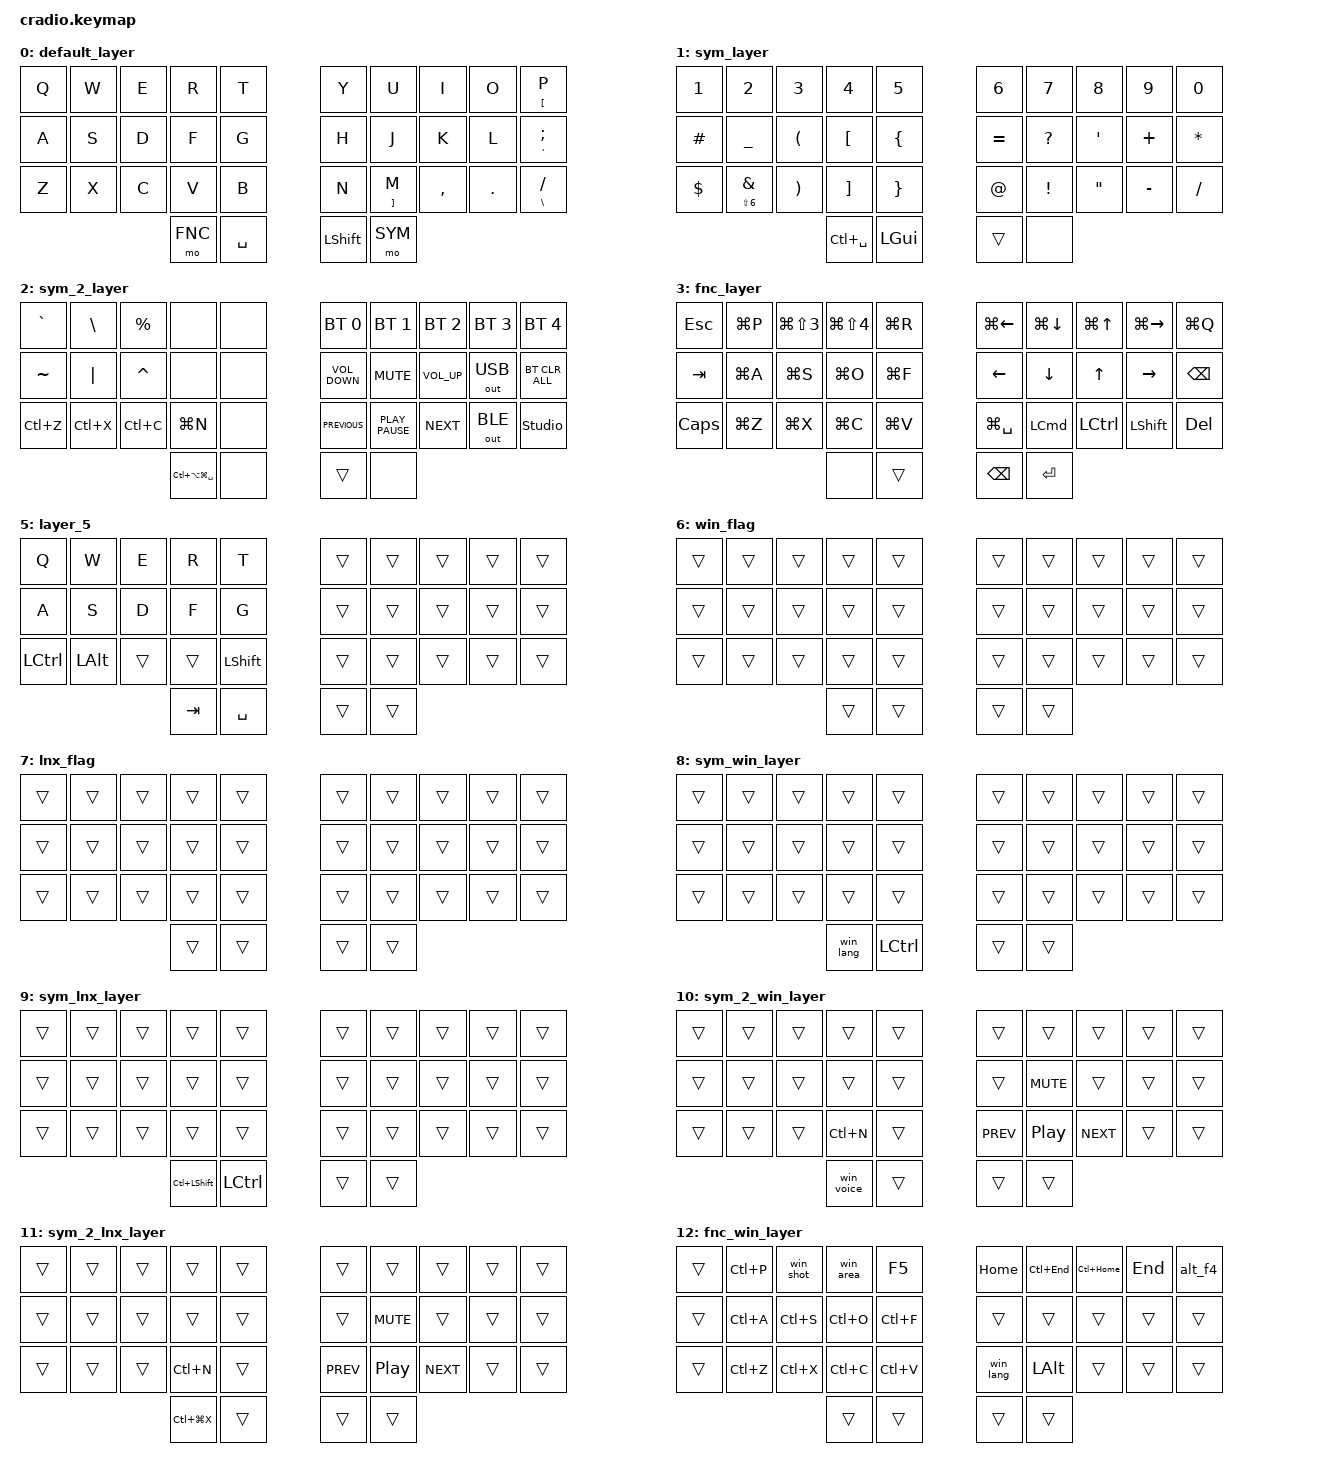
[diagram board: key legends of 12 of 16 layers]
/*
 * Copyright (c) 2020 The ZMK Contributors
 *
 * SPDX-License-Identifier: MIT
 */

#include <behaviors.dtsi>
#include <dt-bindings/zmk/bt.h>
#include <dt-bindings/zmk/keys.h>
#include <dt-bindings/zmk/outputs.h>

#define QWERTY  0
#define SYM     1
#define SYM_2   2
#define FNC     3
#define FNC_2   4
#define GAME    5

/*
 * Режимы ОС.
 *
 * Раскладка одна на все машины: буквы, цифры и символы от ОС не зависят.
 * Зависят сочетания — на Маке копирование это ⌘C, в Windows Ctrl+C, в Omarchy
 * Super+C. Поэтому базой остаётся Мак (основная машина), а под Windows и Linux
 * поднимается ПУСТОЙ флаг-слой, сам по себе ничего не делающий. Через
 * conditional_layers пара «флаг + рабочий слой» поднимает накладку *_W / *_L, в
 * которой переопределены ТОЛЬКО отличающиеся клавиши, остальные &trans и
 * проваливаются на маковские.
 *
 * Режим выбирается сам по BLE-профилю: профиль 1 — Мак, профиль 2 — Windows,
 * профиль 3 — Linux (dongle/src/os_profile.c слушает смену профиля). Вручную —
 * парные нажатия на слое SYM_2: R+T это Мак, F+G это Windows, V+B это Linux
 * (нужно при выводе по USB, где профиля нет). Одиночных клавиш режима тут
 * больше нет: слой SYM_2 включается комбо больших пальцев сам, и буква из
 * того столбца меняла режим при обычной печати. Ручной выбор держится до
 * следующей СМЕНЫ профиля: переподключение хоста его не сбивает.
 *
 * Номера слоёв ниже дублируются в Kconfig донгла (SWEEP_DONGLE_OS_LAYER_*) и в
 * layer_names[] в dongle/src/screen.c — при перестановке слоёв править и там.
 */
#define WIN      6
#define LNX      7
#define SYM_W    8
#define SYM_L    9
#define SYM_2_W 10
#define SYM_2_L 11
#define FNC_W   12
#define FNC_L   13
#define FNC_2_W 14
#define FNC_2_L 15

/*
 * Вызов голосового ввода.
 *
 * Мак: Handy по Ctrl+Alt+Cmd+Space. Сочетание выбрано после разбора
 * com.apple.symbolichotkeys.plist: ни одно из 34 включённых системных
 * сочетаний macOS не использует эту комбинацию модификаторов. Три модификатора
 * вдобавок практически исключают совпадение с сочетаниями внутри программ.
 * Это же сочетание нужно назначить в самом Handy — клавиатура его лишь шлёт.
 *
 * Windows: встроенный голосовой набор Win+H. Omarchy: voxtype, Super+Ctrl+X.
 */
#define VOICE_MAC &kp LC(LA(LG(SPACE)))
#define VOICE_WIN &win_voice
#define VOICE_LNX &kp LC(LG(X))

/* Смена раскладки RU/EN. Мак — Ctrl+Space, Windows — Win+Space, Omarchy —
   Ctrl+Shift (так настроено у владельца). */
#define LANG_WIN &win_lang
#define LANG_LNX &kp LC(LSHFT)

/*
 * Выбор выхода: USB или BLE.
 *
 * ZMK стартует с preferred_transport = ZMK_TRANSPORT_USB и меняет его ТОЛЬКО
 * биндингом &out; значение потом лежит в настройках. Пока готовы оба выхода,
 * побеждает USB — то есть любой воткнутый кабель, хоть для зарядки донгла,
 * хоть для снятия логов, молча уводит нажатия с BLE. Со стороны это выглядит
 * как «клавиатура не печатает по BLE», хотя половинки, донгл и мак исправны.
 *
 * Без этих двух клавиш вернуть вывод на BLE было нечем: Kconfig на выбор
 * выхода в ZMK нет, только поведение &out.
 */

&mt {
    //  flavor = "tap-preferred";
    // tapping_term_ms = <200>;
};

/ {
    behaviors {
        /*
         * Символ удержанием на буквах P/[, ;/', M/], //\.
         *
         * Тест 11.11.2026 на Windows: при 150 мс без защиты от печати удержание
         * срабатывало посреди слова — «съешъ» вместо «съешь» (M нажата через
         * 150 мс после предыдущей буквы и продержана чуть дольше порога), «\»
         * вместо знака препинания. Сознательное удержание P->[ при этом не
         * получалось.
         *
         * require-prior-idle-ms: нажатие в пределах 200 мс после другой клавиши
         * сразу считается тапом — внутри слова символ удержания не выскочит, и
         * следующей клавише не надо ждать решения. Удержание работает после
         * паузы, как и задумано для скобок и обратного слэша.
         * tapping-term-ms 150 -> 200: медленное одиночное нажатие реже уходит в
         * удержание. Раньше было 300 — от него отказались из-за задержки, а
         * задержку внутри печати теперь снимает require-prior-idle-ms.
         * quick-tap-ms: повторное нажатие той же клавиши с удержанием —
         * автоповтор буквы, а не символ.
         */
        dc: dot_comma {
            compatible = "zmk,behavior-hold-tap";
            #binding-cells = <2>;
            tapping-term-ms = <200>;
            require-prior-idle-ms = <200>;
            quick-tap-ms = <200>;
            flavor = "tap-preferred";
            bindings = <&kp>, <&kp>;
        };

        /* ⌘⌫ с Мака: стереть до начала строки. В Windows и Linux отдельного
           сочетания нет, поэтому выделяем до начала строки и стираем. */
        del_bol: delete_to_line_start {
            compatible = "zmk,behavior-macro";
            #binding-cells = <0>;
            bindings = <&kp LS(HOME) &kp BSPC>;
        };
    };

    /*
     * Сочетания с клавишей Win, разнесённые по времени.
     *
     * `&kp LG(SPACE)` отдаёт модификатор и клавишу практически одним HID-
     * отчётом, и Windows успевает увидеть только Win: на отпускании
     * открывается «Пуск», а язык не переключается. Меню «Пуск» в Windows
     * открывается по ОДИНОЧНОМУ нажатию Win, поэтому любая промашка с
     * порядком отчётов выглядит именно так.
     *
     * Макрос давит Win, ждёт, отдельным отчётом тапает клавишу и только потом
     * отпускает Win. 30 мс на шаг — с запасом для обработчика оболочки и
     * незаметно на руке: всё сочетание укладывается в 90 мс.
     *
     * На Маке и в Omarchy этой беды нет, там `&kp` с модификатором оставлен.
     */
    macros {
        win_lang: windows_language_switch {
            compatible = "zmk,behavior-macro";
            #binding-cells = <0>;
            wait-ms = <30>;
            tap-ms = <30>;
            bindings = <&macro_press &kp LGUI>
                     , <&macro_tap &kp SPACE>
                     , <&macro_release &kp LGUI>;
        };

        win_voice: windows_voice_typing {
            compatible = "zmk,behavior-macro";
            #binding-cells = <0>;
            wait-ms = <30>;
            tap-ms = <30>;
            bindings = <&macro_press &kp LGUI>
                     , <&macro_tap &kp H>
                     , <&macro_release &kp LGUI>;
        };

        win_shot: windows_screenshot {
            compatible = "zmk,behavior-macro";
            #binding-cells = <0>;
            wait-ms = <30>;
            tap-ms = <30>;
            bindings = <&macro_press &kp LGUI>
                     , <&macro_tap &kp PSCRN>
                     , <&macro_release &kp LGUI>;
        };

        /*
         * Alt+F4 и Alt+Tab тоже макросами: Windows требует, чтобы Alt был
         * зажат ДО клавиши, а одним HID-отчётом это не гарантируется.
         * Alt+Tab одиночным тапом переключает на предыдущее окно — именно то,
         * чего ждёшь от «переключить окно».
         */
        alt_f4: windows_close_window {
            compatible = "zmk,behavior-macro";
            #binding-cells = <0>;
            wait-ms = <30>;
            tap-ms = <30>;
            bindings = <&macro_press &kp LALT>
                     , <&macro_tap &kp F4>
                     , <&macro_release &kp LALT>;
        };

        alt_tab: switch_window {
            compatible = "zmk,behavior-macro";
            #binding-cells = <0>;
            wait-ms = <30>;
            tap-ms = <30>;
            bindings = <&macro_press &kp LALT>
                     , <&macro_tap &kp TAB>
                     , <&macro_release &kp LALT>;
        };

        win_area: windows_screenshot_area {
            compatible = "zmk,behavior-macro";
            #binding-cells = <0>;
            wait-ms = <30>;
            tap-ms = <30>;
            bindings = <&macro_press &kp LGUI &kp LSHFT>
                     , <&macro_tap &kp S>
                     , <&macro_release &kp LSHFT &kp LGUI>;
        };
    };

    /*
     * ZMK придерживает нажатие клавиши, входящей в комбо, на
     * min(время удержания, timeout-ms) — `app/src/combo.c`, `position_state_down`.
     * Для клавиш, которые держат (&mo, Shift), это всегда полный timeout-ms
     * (zmkfirmware/zmk#2281). Замер 02.10.2026: при 50 мс задерживалось каждое
     * третье нажатие большими пальцами.
     *
     * 30.10.2026 по решению владельца timeout-ms = 25 на всех комбо. При пробе
     * 25 мс на пальцах раньше собирать их было тяжело: если комбо перестанут
     * срабатывать, смотреть сюда.
     */
    combos {
        compatible = "zmk,combos";

        /*
         * ВЕРНУЛИСЬ 08.10.2026. Попытка убрать комбо и переключать слои
         * клавишей внутри слоя провалилась: &tog встал на пальцы Shift и
         * пробела, и обычный порядок «зажать SYM, нажать Shift» стал
         * переключать слой вместо шифта. Пока нет проверенной замены, лучше
         * платить 50 мс на каждом третьем нажатии, чем терять Shift.
         *
         * Цена задержки измерена и описана в README шилда; замена будет
         * выбрана по разбору реальных раскладок, а не на ходу.
         */
        combo_sym2 {
            timeout-ms = <25>;
            require-prior-idle-ms = <150>;
            key-positions = <32 33>;
            bindings = <&tog SYM_2>;
        };

        combo_fun2 {
            timeout-ms = <25>;
            require-prior-idle-ms = <150>;
            key-positions = <30 31>;
            bindings = <&tog FNC_2>;
        };

        /*
         * Ручной выбор режима ОС — ПАРНЫМИ нажатиями, а не одиночной клавишей.
         *
         * Одиночные стояли на SYM_2 в столбце T/G/B и приводили к «раскладка
         * сама меняется с mac на lnx при живом профиле BT1»: слой SYM_2
         * включается комбо больших пальцев само, при обычном накате, и буква
         * из этого столбца попадала по клавише режима. Пара соседних клавиш в
         * пределах 50 мс случайно не собирается.
         *
         * layers перечислены все три, потому что ZMK сверяет комбо с САМЫМ
         * ВЕРХНИМ активным слоем (combo.c: zmk_keymap_highest_layer_active), а
         * в режимах Windows и Linux поверх SYM_2 стоит его накладка.
         */
        combo_os_mac {
            timeout-ms = <25>;
            key-positions = <3 4>;
            bindings = <&to QWERTY>;
            layers = <SYM_2 SYM_2_W SYM_2_L>;
        };

        combo_os_win {
            timeout-ms = <25>;
            key-positions = <13 14>;
            bindings = <&to WIN>;
            layers = <SYM_2 SYM_2_W SYM_2_L>;
        };

        combo_os_lnx {
            timeout-ms = <25>;
            key-positions = <23 24>;
            bindings = <&to LNX>;
            layers = <SYM_2 SYM_2_W SYM_2_L>;
        };
    };

    /*
     * Накладки ОС. Поднимаются, только когда активен флаг-слой режима, и
     * гасятся сами, как только рабочий слой отпущен. Номера накладок выше
     * номеров своих условий — иначе ZMK брал бы биндинг с нижнего слоя.
     */
    conditional_layers {
        compatible = "zmk,conditional-layers";

        sym_win   { if-layers = <SYM WIN>;   then-layer = <SYM_W>;   };
        sym_lnx   { if-layers = <SYM LNX>;   then-layer = <SYM_L>;   };
        sym2_win  { if-layers = <SYM_2 WIN>; then-layer = <SYM_2_W>; };
        sym2_lnx  { if-layers = <SYM_2 LNX>; then-layer = <SYM_2_L>; };
        fnc_win   { if-layers = <FNC WIN>;   then-layer = <FNC_W>;   };
        fnc_lnx   { if-layers = <FNC LNX>;   then-layer = <FNC_L>;   };
        fnc2_win  { if-layers = <FNC_2 WIN>; then-layer = <FNC_2_W>; };
        fnc2_lnx  { if-layers = <FNC_2 LNX>; then-layer = <FNC_2_L>; };
    };

    keymap {
        compatible = "zmk,keymap";

        /*

 | Q | W | E | R | T |       | Y | U | I | O | P |
 | A | S | D | F | G |       | H | J | K | L | ;: |
 | Z | X | C | V | B |       | N | M | ,< | .> | /? |
          | FUN | SHIFT | | SPACE | SYMBOL |
  */

        default_layer {
            bindings = <
&kp Q  &kp W  &kp E  &kp R  &kp T           &kp Y           &kp U       &kp I      &kp O    &dc LBKT P
&kp A  &kp S  &kp D  &kp F  &kp G           &kp H           &kp J       &kp K      &kp L    &dc SQT SEMI
&kp Z  &kp X  &kp C  &kp V  &kp B           &kp N           &dc RBKT M  &kp COMMA  &kp DOT  &dc BSLH SLASH
                     &mo FNC  &kp SPACE     &kp LEFT_SHIFT  &mo SYM
            >;
        };

        /*

 | 1 | 2 | 3 | 4 | 5 |       | 6 | 7 | 8 | 9 | 0 |
 | # | _ | ( | [ | { |       | = | ? | ' | + | * |
 | $ | & | ) | ] | } |       | @ | ! | " | - | / |
             |   | CMD |    |   |   |
  */

        sym_layer {
            bindings = <
&kp NUMBER_1  &kp NUMBER_2  &kp NUMBER_3  &kp NUMBER_4  &kp N5  &kp NUMBER_6  &kp NUMBER_7  &kp NUMBER_8  &kp NUMBER_9  &kp NUMBER_0
&kp HASH  &kp UNDER  &kp LPAR  &kp LBKT  &kp LBRC  &kp EQUAL  &kp QMARK  &kp SQT  &kp PLUS  &kp STAR
&kp DLLR  &dc LS(NUMBER_6) AMPS  &kp RPAR  &kp RBKT  &kp RBRC  &kp AT  &kp EXCL  &kp DQT  &kp MINUS  &kp SLASH
&kp LC(SPACE)  &kp LGUI  &trans  &none
            >;
        };

        /*

 | ` | \ | % |   |   |       |   |   |   |   |   |
 | ~ | | | ^ |   |   |       |   |   |   |   |   |
 |   |   |   |   |   |       |   |   |   |   |   |
             |   |   |       |   |   |
  * Режим ОС — парами: R+T это Мак, F+G это Windows, V+B это Linux.
  */

        sym_2_layer {
            bindings = <
&kp GRAVE  &kp BSLH  &kp PRCNT  &none  &none  &bt BT_SEL 0  &bt BT_SEL 1  &bt BT_SEL 2  &bt BT_SEL 3  &bt BT_SEL 4
&kp TILDE  &kp PIPE  &kp CARET  &none  &none  &kp C_VOLUME_DOWN  &kp K_MUTE  &kp C_VOLUME_UP  &out OUT_USB  &bt BT_CLR_ALL
&kp LC(Z)  &kp LC(X)  &kp LC(C)  &kp LG(N)  &none  &kp K_PREVIOUS  &kp K_PLAY_PAUSE  &kp K_NEXT  &out OUT_BLE  &studio_unlock
VOICE_MAC  &none  &trans  &none
            >;
        };

        /*

 | ESC |   |   |   |   |           |   |   |   |   |   |
 | TAB |   |   |   |   |           | h | j | k | l |   |
 | CAP |   |   |   |   |           |   |   |   |   |   |
      |   |   |           | BSPC | ENTER |
  */
        // &kp LCMD(LS(NUMBER_3))  &kp LCMD(LS(NUMBER_4))  &kp LCMD(LS(NUMBER_5))

        fnc_layer {
            bindings = <
&kp ESC  &kp LG(P)  &kp LG(LS(NUMBER_3))  &kp LG(LS(NUMBER_4))  &kp LG(R)  &kp LG(LEFT)  &kp LG(DOWN)  &kp LG(UP)  &kp LG(RIGHT)  &kp LG(Q)
&kp TAB  &kp LG(A)  &kp LG(S)  &kp LG(O)  &kp LG(F)  &kp LEFT  &kp DOWN  &kp UP  &kp RIGHT  &kp BACKSPACE
&kp CAPS  &kp LG(Z)  &kp LG(X)  &kp LG(C)  &kp LG(V)  &kp LG(SPACE)  &kp LEFT_COMMAND  &kp LEFT_CONTROL  &kp LEFT_SHIFT  &kp DEL
&none  &trans  &kp BSPC  &kp ENTER
            >;
        };

        /*

 | F1 | F2 | F3 | F4 | F5 |           | F6 | F7 | F8 | F9 | F10 |
 |   |   |   |   |   |           |   |   |   |   |   |
 | F11 | F12 |   |   |   |           |   |   |   |   |   |
             |   |   |           |   |   |
  */

        fnc_2_layer {
            bindings = <
&kp F1  &kp F2  &kp F3  &kp F4  &kp F5  &kp F6  &kp F7  &kp F8  &kp F9  &kp F10
&kp LG(Q)  &kp LA(LS(S))  &kp LA(LS(D))  &kp LA(LS(F))  &kp LA(LS(I))  &kp LA(LS(H))  &kp LA(LS(J))  &kp LA(LS(K))  &kp LA(LS(L))  &none
&kp F11  &kp F22  &none  &none  &none  &kp LA(LS(LC(H)))  &kp LA(LS(LC(J)))  &kp LA(LS(LC(K)))  &kp LA(LS(LC(L)))  &kp LG(BACKSPACE)
&none  &trans  &none  &none
            >;
        };

        layer_5 {
            bindings = <
&kp Q      &kp W         &kp E   &kp R    &kp T             &trans  &trans  &trans  &trans  &trans
&kp A      &kp S         &kp D   &kp F    &kp G             &trans  &trans  &trans  &trans  &trans
&kp LCTRL  &kp LEFT_ALT  &trans  &trans   &kp LEFT_SHIFT    &trans  &trans  &trans  &trans  &trans
                                 &kp TAB  &kp SPACE         &trans  &trans
            >;
        };

        /* Флаг режима Windows. Пустой: весь смысл в том, что он включён. */
        win_flag {
            bindings = <
&trans  &trans  &trans  &trans  &trans    &trans  &trans  &trans  &trans  &trans
&trans  &trans  &trans  &trans  &trans    &trans  &trans  &trans  &trans  &trans
&trans  &trans  &trans  &trans  &trans    &trans  &trans  &trans  &trans  &trans
                        &trans  &trans    &trans  &trans
            >;
        };

        /* Флаг режима Linux (Omarchy). */
        lnx_flag {
            bindings = <
&trans  &trans  &trans  &trans  &trans    &trans  &trans  &trans  &trans  &trans
&trans  &trans  &trans  &trans  &trans    &trans  &trans  &trans  &trans  &trans
&trans  &trans  &trans  &trans  &trans    &trans  &trans  &trans  &trans  &trans
                        &trans  &trans    &trans  &trans
            >;
        };

        /* SYM в Windows: смена раскладки Win+Space, большой палец ⌘ -> Ctrl. */
        sym_win_layer {
            bindings = <
&trans  &trans  &trans  &trans     &trans      &trans  &trans  &trans  &trans  &trans
&trans  &trans  &trans  &trans     &trans      &trans  &trans  &trans  &trans  &trans
&trans  &trans  &trans  &trans     &trans      &trans  &trans  &trans  &trans  &trans
                        LANG_WIN   &kp LCTRL   &trans  &trans
            >;
        };

        /* SYM в Omarchy: смена раскладки Ctrl+Shift, большой палец ⌘ -> Ctrl. */
        sym_lnx_layer {
            bindings = <
&trans  &trans  &trans  &trans     &trans      &trans  &trans  &trans  &trans  &trans
&trans  &trans  &trans  &trans     &trans      &trans  &trans  &trans  &trans  &trans
&trans  &trans  &trans  &trans     &trans      &trans  &trans  &trans  &trans  &trans
                        LANG_LNX   &kp LCTRL   &trans  &trans
            >;
        };

        /*
         * SYM_2 в Windows: голосовой набор Win+H, ⌘N -> Ctrl+N и медиа через
         * consumer page. K_MUTE, K_PREVIOUS, K_PLAY_PAUSE и K_NEXT с
         * клавиатурной страницы Windows не понимает, C_* понимают все.
         */
        sym_2_win_layer {
            bindings = <
&trans  &trans  &trans  &trans     &trans    &trans      &trans      &trans      &trans  &trans
&trans  &trans  &trans  &trans     &trans    &trans      &kp C_MUTE  &trans      &trans  &trans
&trans  &trans  &trans  &kp LC(N)  &trans    &kp C_PREV  &kp C_PP    &kp C_NEXT  &trans  &trans
                        VOICE_WIN  &trans    &trans      &trans
            >;
        };

        /* SYM_2 в Omarchy: голосовой набор voxtype, ⌘N -> Ctrl+N, медиа C_*. */
        sym_2_lnx_layer {
            bindings = <
&trans  &trans  &trans  &trans     &trans    &trans      &trans      &trans      &trans  &trans
&trans  &trans  &trans  &trans     &trans    &trans      &kp C_MUTE  &trans      &trans  &trans
&trans  &trans  &trans  &kp LC(N)  &trans    &kp C_PREV  &kp C_PP    &kp C_NEXT  &trans  &trans
                        VOICE_LNX  &trans    &trans      &trans
            >;
        };

        /*
         * FNC в Windows.
         *
         * Снимки экрана: весь экран Win+PrtScr, область Win+Shift+S. Выход
         * Alt+F4. На месте маковского ⌘Space — смена языка Win+Space
         * макросом: у владельца ⌘Space это язык, а не Spotlight, и голая
         * клавиша Win на этом месте открывала «Пуск». Буфер и ⌘ -> Ctrl.
         * ⌘ с Мака на месте M становится Alt: FNC + M + A = Alt+Tab, как ⌘Tab.
         * ⌘стрелки Мака (начало/конец строки и документа) -> Home/End и
         * Ctrl+Home/Ctrl+End.
         */
        fnc_win_layer {
            bindings = <
&trans    &kp LC(P)  &win_shot  &win_area  &kp F5       &kp HOME   &kp LC(END)  &kp LC(HOME)  &kp END  &alt_f4
&trans    &kp LC(A)  &kp LC(S)  &kp LC(O)  &kp LC(F)    &trans     &trans       &trans        &trans   &trans
&trans  &kp LC(Z)  &kp LC(X)      &kp LC(C)      &kp LC(V)    LANG_WIN   &kp LALT     &trans        &trans   &trans
                                  &trans         &trans       &trans     &trans
            >;
        };

        /*
         * FNC в Omarchy.
         *
         * Снимки: меню захвата Super+Ctrl+C, область PrtScr. Закрыть окно
         * Super+W. На месте маковского ⌘Space — смена языка Ctrl+Shift, как
         * настроено у владельца в Omarchy.
         * Копирование Super+X/C/V — работает и в терминале, в отличие от
         * Ctrl+C. Отмена остаётся Ctrl+Z.
         */
        fnc_lnx_layer {
            bindings = <
&trans    &kp LC(P)  &kp LC(LG(C))  &kp PSCRN  &kp F5       &kp HOME  &kp LC(END)  &kp LC(HOME)  &kp END  &kp LG(W)
&alt_tab  &kp LC(A)  &kp LC(S)      &kp LC(O)  &kp LC(F)    &trans    &trans       &trans        &trans   &trans
&trans  &kp LC(Z)  &kp LG(X)      &kp LG(C)  &kp LG(V)    LANG_LNX  &kp LALT     &trans        &trans   &trans
                                  &trans     &trans       &trans    &trans
            >;
        };

        /* FNC_2 в Windows: выход Alt+F4, ⌘⌫ -> выделить до начала строки и
           стереть. Alt+Shift-сочетания одинаковы во всех ОС. */
        fnc_2_win_layer {
            bindings = <
&trans      &trans  &trans  &trans  &trans    &trans  &trans  &trans  &trans  &trans
&kp LA(F4)  &trans  &trans  &trans  &trans    &trans  &trans  &trans  &trans  &trans
&trans      &trans  &trans  &trans  &trans    &trans  &trans  &trans  &trans  &del_bol
                            &trans  &trans    &trans  &trans
            >;
        };

        /* FNC_2 в Omarchy: закрыть окно Super+W, ⌘⌫ -> то же, что в Windows. */
        fnc_2_lnx_layer {
            bindings = <
&trans     &trans  &trans  &trans  &trans    &trans  &trans  &trans  &trans  &trans
&kp LG(W)  &trans  &trans  &trans  &trans    &trans  &trans  &trans  &trans  &trans
&trans     &trans  &trans  &trans  &trans    &trans  &trans  &trans  &trans  &del_bol
                           &trans  &trans    &trans  &trans
            >;
        };
    };
};
